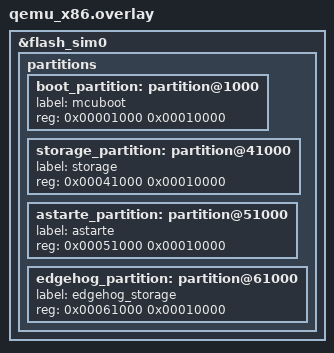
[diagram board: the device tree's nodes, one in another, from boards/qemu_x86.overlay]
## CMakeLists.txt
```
# (C) Copyright 2024, SECO Mind Srl
#
# SPDX-License-Identifier: Apache-2.0

cmake_minimum_required(VERSION 3.20.0)

function(concat_if_exists FILE_PATH STRING_NAME)
    # Check if the file exists
    file(GLOB FILE_TO_ADD ${FILE_PATH})

    # If the file exists, add it to the list
    if(EXISTS ${FILE_TO_ADD})
        set(${STRING_NAME} "${${STRING_NAME}};${FILE_PATH}" PARENT_SCOPE)
    endif()
endfunction()

set(CMAKE_EXPORT_COMPILE_COMMANDS ON)

# add some custom functions from the sample directory
set(SAMPLE_DIR "${CMAKE_CURRENT_LIST_DIR}/../samples/edgehog_app")

# add the sample specific private configuration
concat_if_exists(${CMAKE_SOURCE_DIR}/private.conf EXTRA_CONF_FILE)

find_package(Zephyr REQUIRED HINTS $ENV{ZEPHYR_BASE})
project(e2e_test)

# add sources and includes from the sample dir
target_sources(app PRIVATE ${SAMPLE_DIR}/src/eth.c)
target_include_directories(app PRIVATE ${SAMPLE_DIR}/src/include)

# handle generating certificate inc file
include(certificate.cmake)

# add astarte private headers
target_include_directories(app PRIVATE ${CMAKE_SOURCE_DIR}/../lib/edgehog_device/include)

# add sources
FILE(GLOB app_sources src/*.c)
target_sources(app PRIVATE ${app_sources})
target_include_directories(app PRIVATE include)
```

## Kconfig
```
# (C) Copyright 2024, SECO Mind Srl
#
# SPDX-License-Identifier: Apache-2.0

menu "Zephyr"
source "Kconfig.zephyr"
endmenu

rsource "../Kconfig"

menu "End to end test"

config E2E_ASTARTE_TLS_CERTIFICATE_PATH
	string "Path of the tls root Astarte certificate"
	help
	  Path to a certificate in PEM format. It will be included in the binary and used for TLS
	  authentication with Astarte.
	  This path should be relative to the end to end project folder.

config E2E_EDGEHOG_OTA_TLS_CERTIFICATE_PATH
	string "Path of the tls root Edgehog certificate for OTA"
	help
	  Path to a certificate in PEM format. It will be included in the binary and used for TLS
	  authentication with Edgehog.
	  This path should be relative to the end to end project folder.

config E2E_ASTARTE_DEVICE_ID
	string "Astarte device ID"
    default ""
	help
	  Device ID to be used to connect to Astarte.

config E2E_ASTARTE_CREDENTIAL_SECRET
    string "Astarte credential secret"
    default ""
    help
        The credential secret to be used to connect to Astarte.

config E2E_HTTP_SERVER_DATA_DIR
    string "Directory for HTTP server data"
    default "http_server_data"
    help
        Directory where the HTTP server will store its data.

config E2E_HTTP_SERVER_CERT_DIR
    string "Directory for HTTP server certificates"
    default "http_server_certs"
    help
        Directory where the HTTP server will store its certificates.

config E2E_HTTP_SERVER_PORT
    int "HTTP server port"
    default 8443
    help
        Port on which the HTTP server will listen.

config E2E_APPENGINE_TOKEN
	string "Token to access appengine APIs"
    default ""
	help
	  Token used to access the Astarte appengine APIs.

config E2E_APPENGINE_URL
    string "Url of the appengine APIs"
    default ""
    help
        Url of the appengine APIs exposed by astarte

config E2E_LOG_ONLY
    bool "Enable device log only mode"
    default n
    help
        Incoming astarte server messages will only be logged and no check will be
        performed against incoming data

config E2E_DEVICE_THREAD_STACK_SIZE
    int "Device thread stack size (Bytes)"
    default 8192
    help
        Use this setting to change the size of the stack for the thread running the Astarte device.

config E2E_DEVICE_THREAD_PRIORITY
    int "Device thread priority"
    default 0
    help
        Use this setting to change the priority of the thread running the Astarte device.

config E2E_DEVICE_POLL_PERIOD_MS
    int "Device thread polling period (ms)"
    default 100
    help
        Use this setting to change the polling period for the Astarte device.

config E2E_ETH_POLL_PERIOD_MS
    int "Device thread polling period (ms)"
    default 100
    help
        Use this setting to change the polling period for the ethernet connection.

config E2E_MQTT_CONNECTION_TIMEOUT_MS
    int "MQTT connection timeout (ms)"
    default 3000
    help
        Use this setting to change the MQTT connection timeout.

config E2E_MQTT_POLL_TIMEOUT_MS
    int "MQTT subsequent polling timeout (ms)"
    default 200
    help
        Use this setting to change the MQTT polling timeout.

config E2E_HTTP_TIMEOUT_MS
    int "HTTP operations timeout (ms)"
    default 3000
    help
        Use this setting to change the timeout for HTTP requests.

menu "Logging options"

module = APP
module-str = APP
source "subsys/logging/Kconfig.template.log_config"

module = RUNNER
module-str = Log level for e2e runner and command handler
module-help = Sets log level for e2e runner and command handler
source "subsys/logging/Kconfig.template.log_config"

module = UTILITIES
module-str = Log level for e2e utilities functions
module-help = Sets log level for e2e utilities functions
source "subsys/logging/Kconfig.template.log_config"

module = SHELL_HANDLERS
module-str = Log level for shell handlers
module-help = Sets log level for zephyr shell handlers
source "subsys/logging/Kconfig.template.log_config"

module = DEVICE_HANDLER
module-str = Log level for device handler
module-help = Sets log level for zephyr device handler
source "subsys/logging/Kconfig.template.log_config"

module = DECOMPRESSION
module-str = Log level for decompression
module-help = Sets log level for zephyr decompression
source "subsys/logging/Kconfig.template.log_config"

module = COMPRESSION
module-str = Log level for compression
module-help = Sets log level for zephyr compression
source "subsys/logging/Kconfig.template.log_config"

module = ZTAR
module-str = Log level for ztar
module-help = Sets log level for zephyr ztar
source "subsys/logging/Kconfig.template.log_config"

endmenu

endmenu
```

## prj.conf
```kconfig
# (C) Copyright 2024, SECO Mind Srl
#
# SPDX-License-Identifier: Apache-2.0
#
# This is a Kconfig fragment which can be used to enable debug-related options
# in the application. See the README for more details.

# Increase size for heap allocation space
CONFIG_COMMON_LIBC_MALLOC_ARENA_SIZE=196608

# Increase the UART RX ring buffer to handle long automated commands
CONFIG_SHELL_BACKEND_SERIAL_RX_RING_BUFFER_SIZE=1024
# Ensure the shell command buffer is large enough
CONFIG_SHELL_CMD_BUFF_SIZE=1024
# Prevent the terminal from line-wrapping the echo, which breaks Twister's regex
CONFIG_SHELL_DEFAULT_TERMINAL_WIDTH=1024

# Increase the system workqueue stack
CONFIG_SYSTEM_WORKQUEUE_STACK_SIZE=4096

CONFIG_SHELL=y
CONFIG_SHELL_BACKEND_SERIAL=y
CONFIG_SHELL_BACKEND_SERIAL_LOG_LEVEL_DBG=y

CONFIG_E2E_ASTARTE_TLS_CERTIFICATE_PATH="certificate/astarte.pem"
CONFIG_E2E_EDGEHOG_OTA_TLS_CERTIFICATE_PATH="certificate/edgehog-ota.pem"

CONFIG_DEBUG_OPTIMIZATIONS=y
CONFIG_MBEDTLS_DEBUG=y

# Enable logging with floating point support
CONFIG_LOG=y
CONFIG_CBPRINTF_FP_SUPPORT=y

# Increase minimum heap size.
# TODO: set back the value to 4096 once the file transfer download will not require heap allocation
CONFIG_HEAP_MEM_POOL_SIZE=12288

# Increased stack size
CONFIG_MAIN_STACK_SIZE=16384

# Enable base64 encoding and decoding
CONFIG_BASE64=y

# Enable system hashmaps
CONFIG_SYS_HASH_MAP=y
CONFIG_SYS_HASH_FUNC32=y

# Enable JSON library
CONFIG_JSON_LIBRARY=y

# Enable entropy generator
CONFIG_ENTROPY_GENERATOR=y

# DNS resolver
CONFIG_DNS_RESOLVER=y
CONFIG_DNS_SERVER_IP_ADDRESSES=y
CONFIG_DNS_SERVER1="8.8.8.8" # Google DNS

# Base MbedTLS & heap configuration
CONFIG_MBEDTLS=y
CONFIG_MBEDTLS_BUILTIN=y
CONFIG_MBEDTLS_ENABLE_HEAP=y
CONFIG_MBEDTLS_HEAP_SIZE=95000

# Enable PSA Crypto Backend
CONFIG_PSA_CRYPTO=y
CONFIG_PSA_CRYPTO_ENABLE_ALL=y
CONFIG_MBEDTLS_PSA_CRYPTO_C=y

# TLS & X.509
CONFIG_MBEDTLS_SSL_MAX_CONTENT_LEN=8192
CONFIG_MBEDTLS_PEM_PARSE_C=y
CONFIG_MBEDTLS_PEM_WRITE_C=y
CONFIG_MBEDTLS_BASE64_C=y
CONFIG_MBEDTLS_PK_WRITE_C=y
CONFIG_MBEDTLS_SSL_PROTO_TLS1_2=y
CONFIG_MBEDTLS_SSL_SERVER_NAME_INDICATION=y
CONFIG_MBEDTLS_X509_USE_C=y
CONFIG_MBEDTLS_X509_CRT_PARSE_C=y
CONFIG_MBEDTLS_X509_CRL_PARSE_C=y
CONFIG_MBEDTLS_X509_CSR_PARSE_C=y
CONFIG_MBEDTLS_X509_CSR_WRITE_C=y
CONFIG_MBEDTLS_PKCS5_C=y
CONFIG_MBEDTLS_KEY_EXCHANGE_ECDHE_ECDSA_ENABLED=y
CONFIG_MBEDTLS_KEY_EXCHANGE_ECDHE_RSA_ENABLED=y

# Enable networking
CONFIG_NETWORKING=y

# Sockets
CONFIG_NET_SOCKETS=y
CONFIG_NET_SOCKETS_POLL_MAX=4
CONFIG_NET_SOCKETS_SOCKOPT_TLS=y

# Use DHCP for IPv4 and IPv6
CONFIG_NET_DHCPV4=y
CONFIG_NET_DHCPV6=y

# Generic networking options
CONFIG_NET_TX_STACK_SIZE=4096
CONFIG_NET_RX_STACK_SIZE=4096
CONFIG_NET_PKT_RX_COUNT=20
CONFIG_NET_PKT_TX_COUNT=20
CONFIG_NET_BUF_RX_COUNT=40
CONFIG_NET_BUF_TX_COUNT=40
CONFIG_NET_MAX_CONTEXTS=20
CONFIG_NET_MAX_CONN=6
CONFIG_NET_MGMT=y
CONFIG_NET_MGMT_EVENT=y
CONFIG_NET_IPV4=y
CONFIG_NET_IPV6=y
CONFIG_NET_TCP=y

# Enable HTTP client
CONFIG_HTTP_CLIENT=y

# MQTT options
CONFIG_MQTT_LIB=y
CONFIG_MQTT_LIB_TLS=y
CONFIG_MQTT_KEEPALIVE=60

# Enable flash
CONFIG_FLASH=y
CONFIG_FLASH_MAP=y
CONFIG_FLASH_PAGE_LAYOUT=y

# Enable NVS
CONFIG_NVS=y
CONFIG_NVS_LOG_LEVEL_WRN=y

# Astarte device SDK
CONFIG_ASTARTE_DEVICE_SDK=y
CONFIG_ASTARTE_DEVICE_SDK_HOSTNAME="."
# The two certificate tags are the same as the root CA is the same for Astarte API and MQTT broker.
CONFIG_ASTARTE_DEVICE_SDK_HTTPS_CA_CERT_TAG=1
CONFIG_ASTARTE_DEVICE_SDK_MQTTS_CA_CERT_TAG=1
CONFIG_ASTARTE_DEVICE_SDK_CLIENT_CERT_TAG=2
CONFIG_ASTARTE_DEVICE_SDK_PAIRING_JWT=""
CONFIG_ASTARTE_DEVICE_SDK_REALM_NAME="."

# Edgehog depends on
CONFIG_IMG_MANAGER=y
CONFIG_STREAM_FLASH=y
CONFIG_REBOOT=y

# Edgehog device
CONFIG_EDGEHOG_DEVICE=y
CONFIG_EDGEHOG_DEVICE_OTA_HTTPS_CA_CERT_TAG=3
CONFIG_EDGEHOG_DEVICE_ZBUS_OTA_EVENT=y

# System info interface data
CONFIG_EDGEHOG_DEVICE_PART_NUMBER=""
CONFIG_EDGEHOG_DEVICE_SERIAL_NUMBER=""

# Sample configuration
CONFIG_E2E_ASTARTE_CREDENTIAL_SECRET="."
CONFIG_E2E_ASTARTE_DEVICE_ID="......................"

CONFIG_DNS_RESOLVER_AI_MAX_ENTRIES=4
CONFIG_NET_SOCKETS_TLS_MAX_CONTEXTS=4
CONFIG_TLS_MAX_CREDENTIALS_NUMBER=8

CONFIG_THREAD_MONITOR=y
CONFIG_INIT_STACKS=y
CONFIG_THREAD_STACK_INFO=y

CONFIG_ZVFS_OPEN_MAX=26

CONFIG_SNTP=y
CONFIG_NET_CONFIG_CLOCK_SNTP_INIT=y
CONFIG_NET_CONFIG_SNTP_INIT_SERVER="0.pool.ntp.org"
CONFIG_NET_CONFIG_SNTP_INIT_TIMEOUT=3000

# Enable the settings
CONFIG_SETTINGS=y

# Activate Zbus
CONFIG_ZBUS=y

# Activate thread naming
CONFIG_THREAD_NAME=y

# Enable File System and LittleFS
CONFIG_FILE_SYSTEM=y
CONFIG_FILE_SYSTEM_LITTLEFS=y

# Enable UUID
CONFIG_UUID=y
CONFIG_UUID_V4=y
CONFIG_UUID_V5=y
CONFIG_UUID_BASE64=y

# Enable LZ4 compression
CONFIG_LZ4=y
CONFIG_LZ4_FRAME_SUPPORT=y

# Enable scoped cleanup helpers
CONFIG_SCOPE_CLEANUP_HELPERS=y
```

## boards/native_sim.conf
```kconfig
# (C) Copyright 2024, SECO Mind Srl
#
# SPDX-License-Identifier: Apache-2.0

CONFIG_LOG_BACKEND_NATIVE_POSIX=n
CONFIG_NATIVE_UART_0_ON_STDINOUT=y

CONFIG_PICOLIBC_USE_MODULE=y
CONFIG_PICOLIBC=y

# Ethernet settings
CONFIG_NET_L2_ETHERNET=y
CONFIG_NET_L2_ETHERNET_MGMT=y

# Network application options and configuration
CONFIG_NET_DHCPV4=n
CONFIG_NET_DHCPV6=n
CONFIG_NET_CONFIG_SETTINGS=y
CONFIG_NET_CONFIG_NEED_IPV6=y
CONFIG_NET_CONFIG_MY_IPV6_ADDR="2001:db8::1"
CONFIG_NET_CONFIG_PEER_IPV6_ADDR="2001:db8::2"
CONFIG_NET_CONFIG_NEED_IPV4=y
CONFIG_NET_CONFIG_MY_IPV4_ADDR="192.0.2.1"
CONFIG_NET_CONFIG_PEER_IPV4_ADDR="192.0.2.2"
CONFIG_NET_CONFIG_MY_IPV4_GW="192.0.2.2"
```

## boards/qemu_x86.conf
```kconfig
# (C) Copyright 2026, SECO Mind Srl
#
# SPDX-License-Identifier: Apache-2.0

# Provide enough stack space for MbedTLS crypto and HTTPS handshakes
CONFIG_DEVICE_THREAD_STACK_SIZE=16384
CONFIG_SHELL_STACK_SIZE=16384

# Enable the simulated flash driver for NVS
CONFIG_FLASH_SIMULATOR=y

# Print logs immediately to catch fatal errors before exit
CONFIG_LOG_MODE_IMMEDIATE=y

# Enable PCIe bus to support the e1000 driver
CONFIG_PCIE=y

# QEMU Ethernet settings (emulated e1000)
CONFIG_NET_L2_ETHERNET=y
CONFIG_ETH_E1000=y

# Enable the QEMU network backend
CONFIG_NET_QEMU_ETHERNET=y

# Network application options and configuration
CONFIG_NET_DHCPV4=n
CONFIG_NET_DHCPV6=n
CONFIG_NET_CONFIG_SETTINGS=y
CONFIG_NET_CONFIG_NEED_IPV6=y
CONFIG_NET_CONFIG_MY_IPV6_ADDR="2001:db8::1"
CONFIG_NET_CONFIG_PEER_IPV6_ADDR="2001:db8::2"
CONFIG_NET_CONFIG_NEED_IPV4=y
CONFIG_NET_CONFIG_MY_IPV4_ADDR="192.0.2.1"
CONFIG_NET_CONFIG_PEER_IPV4_ADDR="192.0.2.2"
CONFIG_NET_CONFIG_MY_IPV4_GW="192.0.2.2"
```

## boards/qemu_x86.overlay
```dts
/*
 * (C) Copyright 2026, SECO Mind Srl
 *
 * SPDX-License-Identifier: Apache-2.0
 */

/delete-node/ &storage_partition;

&flash_sim0 {
	partitions {
		boot_partition: partition@1000 {
			label = "mcuboot";
			reg = <0x00001000 0x00010000>;
		};

		storage_partition: partition@41000 {
			label = "storage";
			reg = <0x00041000 0x00010000>;
		};

		astarte_partition: partition@51000 {
			label = "astarte";
			reg = <0x00051000 0x00010000>;
		};

		edgehog_partition: partition@61000 {
			label = "edgehog_storage";
			reg = <0x00061000 0x00010000>;
		};
	};
};
```

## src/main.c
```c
/*
 * (C) Copyright 2024, SECO Mind Srl
 *
 * SPDX-License-Identifier: Apache-2.0
 */

#include <zephyr/kernel.h>
#include <zephyr/logging/log.h>
#include <zephyr/sys/atomic.h>
#include <zephyr/sys/util.h>
#include <zephyr/sys_clock.h>

#if defined(CONFIG_ARCH_POSIX)
#include <nsi_main.h>
#endif

#if !defined(CONFIG_ASTARTE_DEVICE_SDK_DEVELOP_USE_NON_TLS_HTTP)                                   \
    || !defined(CONFIG_ASTARTE_DEVICE_SDK_DEVELOP_USE_NON_TLS_MQTT)
#define NEEDS_TLS
#endif

#if defined(NEEDS_TLS)

// Enable mbed tls debug
#define MBEDTLS_DEBUG_C

#if defined(CONFIG_TLS_CERTIFICATE_PATH)
#include "ca_certificate_inc.h"
#else
#error TLS enabled but no generated certificate found: check the CONFIG_TLS_CERTIFICATE_PATH option
#endif

#include <mbedtls/debug.h>
#include <zephyr/net/tls_credentials.h>

#endif

#include "eth.h"

#include "runner.h"
#include "utilities.h"

LOG_MODULE_REGISTER(main, CONFIG_APP_LOG_LEVEL);

/************************************************
 *       Checks over configuration values       *
 ***********************************************/

/************************************************
 *   Constants, static variables and defines    *
 ***********************************************/

#define ETH_THREAD_STACK_SIZE 4096
K_THREAD_STACK_DEFINE(eth_thread_stack_area, ETH_THREAD_STACK_SIZE);
static struct k_thread eth_thread_data;
enum eth_thread_flags
{
    ETH_THREAD_TERMINATION_FLAG = 0,
};
static atomic_t eth_thread_flags;

/************************************************
 *         Static functions declaration         *
 ***********************************************/

static void eth_thread_entry_point(void *unused1, void *unused2, void *unused3);

/************************************************
 *         Global functions definition          *
 ***********************************************/

int main(void)
{
    LOG_INF("Edgehog device end to end test");

    // Initialize Ethernet driver
    LOG_INF("Initializing Ethernet driver.");
    if (eth_connect() != 0) {
        LOG_ERR("Connectivity intialization failed!");
        return -1;
    }

#if defined(NEEDS_TLS)

    // Add TLS certificate
    tls_credential_add(CONFIG_ASTARTE_DEVICE_SDK_HTTPS_CA_CERT_TAG, TLS_CREDENTIAL_CA_CERTIFICATE,
        ca_certificate_root, ARRAY_SIZE(ca_certificate_root));

    // Enable mbedtls logging
    mbedtls_debug_set_threshold(1);

#endif

    LOG_INF("Spawning a new thread to poll the eth interface and check connectivity.");
    k_thread_create(&eth_thread_data, eth_thread_stack_area,
        K_THREAD_STACK_SIZEOF(eth_thread_stack_area), eth_thread_entry_point, NULL, NULL, NULL,
        CONFIG_DEVICE_THREAD_PRIORITY, 0, K_NO_WAIT);

    LOG_INF("Running the end to end test.");
    run_end_to_end_test();

    atomic_set_bit(&eth_thread_flags, ETH_THREAD_TERMINATION_FLAG);
    CHECK_HALT(k_thread_join(&eth_thread_data, K_FOREVER) != 0,
        "Failed in waiting for the eth polling thread to terminate.");

    LOG_INF("Returning from the end to end test.");

#if defined(CONFIG_ARCH_POSIX)
    // Required to terminate when on posix
    nsi_exit(0);
#endif
    return 0;
}

/************************************************
 *         Static functions definitions         *
 ***********************************************/

static void eth_thread_entry_point(void *unused1, void *unused2, void *unused3)
{
    ARG_UNUSED(unused1);
    ARG_UNUSED(unused2);
    ARG_UNUSED(unused3);

    LOG_INF("Started the eth polling thread");

    while (!atomic_test_bit(&eth_thread_flags, ETH_THREAD_TERMINATION_FLAG)) {
        k_timepoint_t timepoint = sys_timepoint_calc(K_MSEC(CONFIG_ETH_POLL_PERIOD_MS));

        if (eth_poll() != 0) {
            LOG_ERR("Failed polling Ethernet."); // NOLINT
        }

        k_sleep(sys_timepoint_timeout(timepoint));
    }
}
```

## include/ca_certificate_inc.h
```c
/*
 * (C) Copyright 2024, SECO Mind Srl
 *
 * SPDX-License-Identifier: Apache-2.0
 */

#ifndef CA_CERTIFICATE_INC_H
#define CA_CERTIFICATE_INC_H

// ca_certificate.inc is generated at build time by certificate.cmake
static const unsigned char ca_certificate_root[] = {
#include "ca_certificate.inc"
    0x00
};

#endif /* CA_CERTIFICATE_INC_H */
```

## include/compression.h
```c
/*
 * (C) Copyright 2026, SECO Mind Srl
 *
 * SPDX-License-Identifier: Apache-2.0
 */

#ifndef COMPRESSION_H
#define COMPRESSION_H

/**
 * @file compression.h
 * @brief LZ4 Compression context and processing functions
 */

#include <stdbool.h>
#include <stddef.h>
#include <stdint.h>

#include <lz4frame.h>

#ifdef __cplusplus
extern "C" {
#endif

/** @brief Data struct for a compression context instance. */
typedef struct
{
    /** @brief LZ4 compression context. */
    LZ4F_cctx *lz4_cctx;
} compression_ctx_t;

/**
 * @brief Initialize the compression context.
 *
 * @param[in,out] ctx Pointer to the compression context.
 * @return 0 on success, negative value on error.
 */
int compression_init(compression_ctx_t *ctx);

/**
 * @brief Check if the compression context is initialized.
 *
 * @param[in] ctx Pointer to the compression context.
 * @return True if initialized, false if not.
 */
bool compression_is_initialized(const compression_ctx_t *ctx);

/**
 * @brief Start the compression stream and write the frame header.
 *
 * @param[in,out] ctx Pointer to the compression context.
 * @param[out] out Buffer to write the header into.
 * @param[in] out_size Maximum capacity of the destination buffer.
 * @param[out] bytes_written Number of bytes written to the destination buffer.
 * @return 0 on success, negative value on error.
 */
int compression_begin(compression_ctx_t *ctx, uint8_t *out, size_t out_size, size_t *bytes_written);

/**
 * @brief Compress a chunk of data.
 *
 * @param[in,out] ctx Pointer to the compression context.
 * @param[in] input Pointer to the uncompressed source data.
 * @param[in] input_size Size of the uncompressed source data.
 * @param[out] out Buffer to write the compressed data into.
 * @param[in] out_size Maximum capacity of the destination buffer.
 * @param[out] bytes_written Number of bytes written to the destination buffer.
 * @return 0 on success, negative value on error.
 */
int compression_update(compression_ctx_t *ctx, const uint8_t *input, size_t input_size,
    uint8_t *out, size_t out_size, size_t *bytes_written);

/**
 * @brief Finalize the compression stream and write the frame footer.
 *
 * @param[in,out] ctx Pointer to the compression context.
 * @param[out] out Buffer to write the footer into.
 * @param[in] out_size Maximum capacity of the destination buffer.
 * @param[out] bytes_written Number of bytes written to the destination buffer.
 * @return 0 on success, negative value on error.
 */
int compression_end(compression_ctx_t *ctx, uint8_t *out, size_t out_size, size_t *bytes_written);

/**
 * @brief Free the compression context.
 *
 * @param[in,out] ctx Pointer to the compression context.
 */
void compression_free(compression_ctx_t *ctx);

#ifdef __cplusplus
}
#endif

#endif /* COMPRESSION_H */
```

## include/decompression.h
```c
/*
 * (C) Copyright 2026, SECO Mind Srl
 *
 * SPDX-License-Identifier: Apache-2.0
 */

#ifndef DECOMPRESSION_H
#define DECOMPRESSION_H

/**
 * @file decompression.h
 * @brief LZ4 Decompression context and processing functions
 */

#include <stdbool.h>
#include <stddef.h>
#include <stdint.h>

#include <lz4frame.h>

#ifdef __cplusplus
extern "C" {
#endif

/**
 * @typedef decompression_write_data_cbk_t
 * @brief Callback used when a chunk of decompressed data is ready to be written.
 *
 * @param[in] data Pointer to the decompressed data chunk.
 * @param[in] size Size of the decompressed data chunk.
 * @param[in,out] user_data User specified data passed during initialization.
 *
 * @return 0 if successful, otherwise a negative error code.
 */
typedef int (*decompression_write_data_cbk_t)(const uint8_t *data, size_t size, void *user_data);

/** @brief Data struct for a decompression context instance. */
typedef struct
{
    /** @brief LZ4 decompression context. */
    LZ4F_dctx *lz4_dctx;
    /** @brief Buffer used for intermediate decompressed data. */
    uint8_t *decomp_buf;
    /** @brief Callback for writing decompressed data. */
    decompression_write_data_cbk_t write_data_cbk;
    /** @brief User data passed to write_data_cbk callback function. */
    void *user_data;
} decompression_ctx_t;

/**
 * @brief Initialize the decompression context.
 * @note Calling this function on an already initialized context will return an error.
 *
 * @param[in,out] ctx Pointer to the decompression context.
 * @param[in] write_data_cbk Callback to execute when data is decompressed.
 * @param[in] user_data User specified data to pass to the callback.
 * @return 0 on success, negative value on error.
 */
int decompression_init(
    decompression_ctx_t *ctx, decompression_write_data_cbk_t write_data_cbk, void *user_data);

/**
 * @brief Check if the decompression context is initialized.
 *
 * @param[in] ctx Pointer to the decompression context.
 * @return True if initialized, false if not.
 */
bool decompression_is_initialized(const decompression_ctx_t *ctx);

/**
 * @brief Decompress a chunk of data and pass it to the write callback.
 *
 * @param[in,out] ctx Pointer to the decompression context.
 * @param[in] src Pointer to the compressed source data.
 * @param[in] src_size Size of the compressed source data.
 * @return 0 on success, negative value on error.
 */
int decompression_process_chunk(decompression_ctx_t *ctx, const uint8_t *src, size_t src_size);

/**
 * @brief Free the decompression context.
 *
 * @param[in,out] ctx Pointer to the decompression context.
 */
void decompression_free(decompression_ctx_t *ctx);

#ifdef __cplusplus
}
#endif

#endif /* DECOMPRESSION_H */
```

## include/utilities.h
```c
/*
 * (C) Copyright 2024, SECO Mind Srl
 *
 * SPDX-License-Identifier: Apache-2.0
 */

#ifndef UTILITIES_H
#define UTILITIES_H

#include <stdint.h>

#include <zephyr/fatal.h>
#include <zephyr/shell/shell.h>

#define CHECK_HALT(expr, ...)                                                                      \
    if (expr) {                                                                                    \
        LOG_ERR(__VA_ARGS__);                                                                      \
        k_fatal_halt(-1);                                                                          \
    }

#define CHECK_ASTARTE_OK_HALT(expr, ...) CHECK_HALT(expr != ASTARTE_RESULT_OK, __VA_ARGS__)

#define CHECK_RET_1(expr, ...)                                                                     \
    if (expr) {                                                                                    \
        __VA_OPT__(LOG_ERR(__VA_ARGS__));                                                          \
        return 1;                                                                                  \
    }

#define CHECK_ASTARTE_OK_RET_1(expr, ...) CHECK_RET_1(expr != ASTARTE_RESULT_OK, __VA_ARGS__)

#define CHECK_GOTO(expr, label, ...)                                                               \
    if (expr) {                                                                                    \
        LOG_ERR(__VA_ARGS__);                                                                      \
        goto label;                                                                                \
    }

#define CHECK_ASTARTE_OK_GOTO(expr, label, ...)                                                    \
    CHECK_GOTO(expr != ASTARTE_RESULT_OK, label, __VA_ARGS__)

#endif /* UTILITIES_H */
```

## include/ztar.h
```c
#ifndef ZTAR_H
#define ZTAR_H

/**
 * @file ztar.h
 * @brief Tar archive extraction and packing stream parser.
 * @details This parser only supports the USTAR format and is designed to work with streaming data,
 * making it suitable for processing large tar archives without needing to load the entire archive
 * into memory. It provides callbacks for file start, file data, and file end events, allowing users
 * to handle extracted files as they are processed from the stream. It also supports packing files
 * into a stream.
 */

#include <stdbool.h>
#include <stddef.h>
#include <stdint.h>

#ifdef __cplusplus
extern "C" {
#endif

/** @brief Result codes for ztar stream operations. */
typedef enum
{
    /** @brief Operation completed successfully. */
    ZTAR_RESULT_OK = 0,
    /** @brief Internal error, should not occur. */
    ZTAR_RESULT_INTERNAL_ERROR,
    /** @brief Invalid arguments provided to the function. */
    ZTAR_RESULT_INVALID_ARGS,
    /** @brief The archive format is invalid. */
    ZTAR_RESULT_INVALID_ARCHIVE,
    /** @brief The provided buffer is insufficient. */
    ZTAR_RESULT_INSUFFICIENT_BUFF,
    /** @brief The TAR magic indicator is invalid. */
    ZTAR_RESULT_INVALID_MAGIC,
    /** @brief The TAR version is invalid. */
    ZTAR_RESULT_INVALID_VERSION,
    /** @brief The checksum of the header is invalid. */
    ZTAR_RESULT_INVALID_CHECKSUM,
    /** @brief The file within the archive is truncated. */
    ZTAR_RESULT_TRUNCATED_FILE,
    /** @brief The archive itself is truncated. */
    ZTAR_RESULT_TRUNCATED_ARCHIVE,
    /** @brief The archive stream has been fully exhausted. */
    ZTAR_RESULT_ARCHIVE_EXAHUSTED,
    /** @brief The user callback returned an error. */
    ZTAR_RESULT_USER_CBK_ERROR,
} ztar_result_t;

/** @brief Extracted TAR file types. */
typedef enum
{
    /** @brief Standard regular file. */
    ZTAR_REGULAR_FILE,
    /** @brief Directory file type. */
    ZTAR_DIRECTORY,
    /** @brief Handles symlinks, hardlinks, FIFOs, and PAX extension headers. */
    ZTAR_UNSUPPORTED
} ztar_filetype_t;

/**
 * @brief Standard POSIX TAR header structure.
 * @note This structure is exactly 512 bytes, which is the size of a TAR header block. It relies
 * on the compiler not adding any padding between fields, which is generally safe given the
 * use of only char arrays and single char fields, but should be verified if any changes are made.
 */
typedef struct
{
    /** @brief Name of the file. */
    char name[100];
    /** @brief File permissions mode. */
    char mode[8];
    /** @brief Numeric user ID of the file owner. */
    char uid[8];
    /** @brief Numeric group ID of the file owner. */
    char gid[8];
    /** @brief File size in bytes (octal string). */
    char size[12];
    /** @brief Last modification time in numeric Unix time format. */
    char mtime[12];
    /** @brief Checksum for the header block. */
    char chksum[8];
    /** @brief Link indicator / file type flag. */
    char typeflag;
    /** @brief Name of the linked file. */
    char linkname[100];
    /** @brief UStar magic indicator ("ustar"). */
    char magic[6];
    /** @brief UStar version ("00"). */
    char version[2];
    /** @brief Owner user name. */
    char uname[32];
    /** @brief Owner group name. */
    char gname[32];
    /** @brief Device major number. */
    char devmajor[8];
    /** @brief Device minor number. */
    char devminor[8];
    /** @brief Prefix for the file name. */
    char prefix[155];
    /** @brief Padding to fill the 512-byte block. */
    char padding[12];
} ztar_header_t;

/** @brief Callbacks for ztar stream parsing events. */
typedef struct
{
    /**
     * @brief Callback invoked when a new file starts in the archive.
     *
     * @param[in] header Pointer to the parsed TAR header.
     * @param[in,out] user_data User specified data.
     * @return 0 if successful, -1 on error. The stream parser will abort if an error is returned.
     */
    int (*on_file_start)(const ztar_header_t *header, void *user_data);

    /**
     * @brief Callback invoked when file data is read from the stream.
     *
     * @param[in] header Pointer to the parsed TAR header.
     * @param[in] data Pointer to the file data chunk.
     * @param[in] size Size of the file data chunk.
     * @param[in,out] user_data User specified data.
     * @return 0 if successful, -1 on error. The stream parser will abort if an error is returned.
     */
    int (*on_file_data)(
        const ztar_header_t *header, const uint8_t *data, size_t size, void *user_data);

    /**
     * @brief Callback invoked when a file ends in the archive.
     *
     * @param[in] header Pointer to the parsed TAR header.
     * @param[in,out] user_data User specified data.
     * @return 0 if successful, -1 on error. The stream parser will abort if an error is returned.
     */
    int (*on_file_end)(const ztar_header_t *header, void *user_data);
} ztar_unpack_callbacks_t;

/** @brief Internal states of the TAR stream parser. */
typedef enum
{
    /** @brief Parser is currently reading a header block. */
    ZTAR_UNPACK_STATE_HEADER = 0,
    /** @brief Parser is currently reading file data. */
    ZTAR_UNPACK_STATE_DATA,
    /** @brief Parser is currently reading file padding blocks. */
    ZTAR_UNPACK_STATE_PADDING,
    /** @brief Parser is reading the archive end trailer blocks. */
    ZTAR_UNPACK_STATE_TRAILER
} ztar_unpack_state_t;

/** @brief Data struct for a ztar stream parser instance. */
typedef struct
{
    /** @brief Indicates if the stream parser has been initialized. */
    bool initialized;
    /** @brief Current internal state of the stream parser. */
    ztar_unpack_state_t state;
    /** @brief The TAR header currently being processed. */
    ztar_header_t current_header;
    /** @brief Number of bytes processed in the current header. */
    size_t bytes_processed_in_header;
    /** @brief Number of bytes processed in the current file data. */
    size_t bytes_processed_in_file;
    /** @brief Number of bytes processed in the current file's block padding. */
    size_t bytes_processed_in_padding;
    /** @brief Number of bytes processed in the archive trailer. */
    size_t bytes_processed_in_trailer;
    /** @brief Registered callbacks for parsing events. */
    ztar_unpack_callbacks_t callbacks;
    /** @brief User data passed to callback functions. */
    void *user_data;
} ztar_unpack_t;

/**
 * @brief Initialize the ztar stream parser.
 *
 * @param[in,out] stream Pointer to the ztar stream to initialize.
 * @param[in] callbacks Struct containing parser event callbacks.
 * @param[in] user_data User specified data to pass to the callbacks.
 * @return ZTAR_RESULT_OK if successful, otherwise a ztar_result_t error code.
 */
ztar_result_t ztar_unpack_init(
    ztar_unpack_t *stream, ztar_unpack_callbacks_t callbacks, void *user_data);

/**
 * @brief Check if the ztar stream parser is initialized.
 *
 * @param[in] stream Pointer to the ztar stream.
 * @return True if initialized, false if not.
 */
bool ztar_unpack_is_initialized(const ztar_unpack_t *stream);

/**
 * @brief Process a chunk of data through the TAR stream parser.
 *
 * @param[in,out] stream Pointer to the initialized ztar stream.
 * @param[in] data Pointer to the chunk of TAR archive data.
 * @param[in] size Size of the TAR archive data chunk.
 * @return ZTAR_RESULT_OK if successful, otherwise a ztar_result_t error code.
 */
ztar_result_t ztar_unpack_process(ztar_unpack_t *stream, const uint8_t *data, size_t size);

/**
 * @brief Extract the full file name from a parsed TAR header.
 * @details In USTAR, if the prefix is populated, the full path is prefix + '/' + name.
 *
 * @param[in] header Pointer to the parsed TAR header.
 * @param[out] buffer Output buffer for the file name (must be at least 257 bytes).
 * @return ZTAR_RESULT_OK if successful, otherwise a ztar_result_t error code.
 */
ztar_result_t ztar_unpack_get_file_name(const ztar_header_t *header, char buffer[static 257]);

/**
 * @brief Extract the file size from a parsed TAR header.
 *
 * @param[in] header Pointer to the parsed TAR header.
 * @param[out] file_size Output pointer for the extracted file size.
 * @return ZTAR_RESULT_OK if successful, otherwise a ztar_result_t error code.
 */
ztar_result_t ztar_unpack_get_file_size(const ztar_header_t *header, size_t *file_size);

/**
 * @brief Extract the file type from a parsed TAR header.
 * @details Restricts output strictly to regular files and directories, all other types are
 * considered unsupported.
 *
 * @param[in] header Pointer to the parsed TAR header.
 * @param[out] file_type Output pointer for the extracted file type.
 * @return ZTAR_RESULT_OK if successful, otherwise a ztar_result_t error code.
 */
ztar_result_t ztar_unpack_get_file_type(const ztar_header_t *header, ztar_filetype_t *file_type);

/** @brief Internal states of the TAR stream packer. */
typedef enum
{
    ZTAR_PACK_STATE_NEXT_FILE = 0,
    ZTAR_PACK_STATE_HEADER,
    ZTAR_PACK_STATE_DATA,
    ZTAR_PACK_STATE_PADDING,
    ZTAR_PACK_STATE_TRAILER,
    ZTAR_PACK_STATE_DONE
} ztar_pack_state_t;

/** @brief Callbacks for ztar stream packing events. */
typedef struct
{
    /**
     * @brief Called when the packer needs the next file's metadata.
     * @param[out] has_next Pointer to a boolean indicating if there are more files.
     * @param[out] name Buffer to copy the file name into.
     * @param[out] size Pointer to write the file size into.
     * @param[in] user_data User specified data.
     * @return 0 on success, -1 on error.
     */
    int (*get_next_file)(bool *has_next, char name[static 257], size_t *size, void *user_data);

    /**
     * @brief Called when the packer needs raw file data.
     * @param[out] buffer Destination buffer for the file data.
     * @param[in] max_size Maximum number of bytes to read.
     * @param[in] user_data User specified data.
     * @param[out] bytes_read Pointer to write the actual number of bytes read into.
     * @return 0 on success, -1 on error.
     */
    int (*read_file_data)(uint8_t *buffer, size_t max_size, void *user_data, size_t *bytes_read);
} ztar_pack_callbacks_t;

/** @brief Data struct for a ztar stream packer instance. */
typedef struct
{
    /** @brief Indicates if the stream packer has been initialized. */
    bool initialized;
    ztar_pack_state_t state;
    char current_file_name[257];
    /** @brief Expected size of the file currently being packed. */
    size_t expected_file_size;
    /** @brief Number of bytes written for the current file data so far. */
    size_t bytes_written_for_file;
    size_t bytes_processed_in_padding;
    size_t bytes_processed_in_trailer;
    ztar_pack_callbacks_t callbacks;
    void *user_data;
} ztar_pack_t;

ztar_result_t ztar_pack_init(ztar_pack_t *stream, ztar_pack_callbacks_t callbacks, void *user_data);

bool ztar_pack_is_initialized(const ztar_pack_t *stream);

ztar_result_t ztar_pack_read_stream(
    ztar_pack_t *stream, uint8_t *out_buffer, size_t out_size, size_t *bytes_written);

#ifdef __cplusplus
}
#endif

#endif
```

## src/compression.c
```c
/*
 * (C) Copyright 2026, SECO Mind Srl
 *
 * SPDX-License-Identifier: Apache-2.0
 */

#include "compression.h"

#include <stdlib.h>
#include <string.h>

#include <zephyr/logging/log.h>

LOG_MODULE_REGISTER(compression, CONFIG_COMPRESSION_LOG_LEVEL);

// Static preferences for the LZ4 compression
static const LZ4F_preferences_t lz4_prefs = {
    .autoFlush = 1,
};

int compression_init(compression_ctx_t *ctx)
{
    if (!ctx || ctx->lz4_cctx) {
        return -1;
    }
    LOG_DBG("Initializing compression context");

    size_t ret = LZ4F_createCompressionContext(&ctx->lz4_cctx, LZ4F_VERSION);
    if (LZ4F_isError(ret)) {
        LOG_ERR("Failed to create LZ4 compression context: %s", LZ4F_getErrorName(ret));
        return -1;
    }

    return 0;
}

bool compression_is_initialized(const compression_ctx_t *ctx)
{
    return ctx && ctx->lz4_cctx != NULL;
}

int compression_begin(compression_ctx_t *ctx, uint8_t *out, size_t out_size, size_t *bytes_written)
{
    if (!ctx || !ctx->lz4_cctx)
        return -1;

    size_t ret = LZ4F_compressBegin(ctx->lz4_cctx, out, out_size, &lz4_prefs);
    if (LZ4F_isError(ret)) {
        LOG_ERR("LZ4 compress begin failed: %s", LZ4F_getErrorName(ret));
        return -1;
    }

    *bytes_written = ret;
    return 0;
}

int compression_update(compression_ctx_t *ctx, const uint8_t *input, size_t input_size,
    uint8_t *out, size_t out_size, size_t *bytes_written)
{
    if (!ctx || !ctx->lz4_cctx)
        return -1;

    size_t ret = LZ4F_compressUpdate(ctx->lz4_cctx, out, out_size, input, input_size, NULL);
    if (LZ4F_isError(ret)) {
        LOG_ERR("LZ4 compression failed: %s", LZ4F_getErrorName(ret));
        return -1;
    }

    *bytes_written = ret;
    return 0;
}

int compression_end(compression_ctx_t *ctx, uint8_t *out, size_t out_size, size_t *bytes_written)
{
    if (!ctx || !ctx->lz4_cctx)
        return -1;

    size_t ret = LZ4F_compressEnd(ctx->lz4_cctx, out, out_size, NULL);
    if (LZ4F_isError(ret)) {
        LOG_ERR("LZ4 footer write failed: %s", LZ4F_getErrorName(ret));
        return -1;
    }

    *bytes_written = ret;
    return 0;
}

void compression_free(compression_ctx_t *ctx)
{
    if (ctx && ctx->lz4_cctx) {
        LOG_DBG("Freeing compression context");
        LZ4F_freeCompressionContext(ctx->lz4_cctx);
        ctx->lz4_cctx = NULL;
    }
}
```

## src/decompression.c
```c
/*
 * (C) Copyright 2026, SECO Mind Srl
 *
 * SPDX-License-Identifier: Apache-2.0
 */

#include "decompression.h"

#include <stdlib.h>
#include <string.h>

#include <zephyr/logging/log.h>

LOG_MODULE_REGISTER(decompression, CONFIG_DECOMPRESSION_LOG_LEVEL);

#define DECOMP_BUF_SIZE 4096

int decompression_init(
    decompression_ctx_t *ctx, decompression_write_data_cbk_t write_data_cbk, void *user_data)
{
    if (!ctx || ctx->lz4_dctx) {
        return -1;
    }
    if (!write_data_cbk) {
        LOG_ERR("No write callback provided for decompression context");
        return -1;
    }
    LOG_DBG("Initializing decompression context");

    LZ4F_dctx *lz4_dctx = NULL;
    uint8_t *decomp_buf = NULL;

    decomp_buf = malloc(DECOMP_BUF_SIZE);
    if (!decomp_buf) {
        LOG_ERR("Failed to allocate decompression buffer");
        goto failure;
    }

    size_t ret = LZ4F_createDecompressionContext(&lz4_dctx, LZ4F_VERSION);
    if (LZ4F_isError(ret)) {
        LOG_ERR("Failed to create LZ4 context: %s", LZ4F_getErrorName(ret));
        goto failure;
    }

    ctx->lz4_dctx = lz4_dctx;
    ctx->decomp_buf = decomp_buf;
    ctx->write_data_cbk = write_data_cbk;
    ctx->user_data = user_data;
    return 0;

failure:
    free(decomp_buf);
    if (lz4_dctx) {
        LZ4F_freeDecompressionContext(lz4_dctx);
    }
    return -1;
}

bool decompression_is_initialized(const decompression_ctx_t *ctx)
{
    return ctx && ctx->lz4_dctx != NULL;
}

int decompression_process_chunk(decompression_ctx_t *ctx, const uint8_t *src, size_t src_size)
{
    if (!ctx || !ctx->lz4_dctx) {
        return -1;
    }
    LOG_DBG("Processing chunk of size %zu", src_size);

    const uint8_t *src_cursor = src;
    size_t src_remaining = src_size;
    bool flush_needed = false;

    while (src_remaining > 0 || flush_needed) {
        size_t dst_consumed = DECOMP_BUF_SIZE;
        size_t src_consumed = src_remaining;

        size_t ret = LZ4F_decompress(
            ctx->lz4_dctx, ctx->decomp_buf, &dst_consumed, src_cursor, &src_consumed, NULL);
        if (LZ4F_isError(ret)) {
            LOG_ERR("Decompression error: %s", LZ4F_getErrorName(ret));
            return -1;
        }

        if (dst_consumed > 0) {
            LOG_DBG("Extracted %zu uncompressed bytes", dst_consumed);

            int write_ret = ctx->write_data_cbk(ctx->decomp_buf, dst_consumed, ctx->user_data);
            if (write_ret < 0) {
                LOG_ERR("Failed to write decompressed data");
                return -1;
            }
        }

        src_cursor += src_consumed;
        src_remaining -= src_consumed;

        // If LZ4 completely filled the destination buffer, it likely has more data
        // buffered internally. We must loop again to flush it, even if src_remaining == 0.
        flush_needed = (dst_consumed == DECOMP_BUF_SIZE);
    }

    return 0;
}

void decompression_free(decompression_ctx_t *ctx)
{
    if (ctx) {
        LOG_DBG("Freeing decompression context");
        free(ctx->decomp_buf);
        ctx->decomp_buf = NULL;
        if (ctx->lz4_dctx) {
            LZ4F_freeDecompressionContext(ctx->lz4_dctx);
            ctx->lz4_dctx = NULL;
        }
    }
}
```
